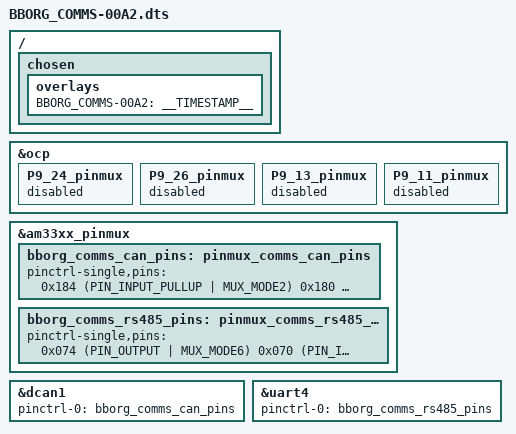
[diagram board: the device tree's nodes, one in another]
/*
 * Copyright (C) 2012,2019 Texas Instruments Incorporated - http://www.ti.com/
 * Copyright (C) 2015 Robert Nelson <robertcnelson@gmail.com>
 * Copyright (C) 2015 Sebastian Jegerås
 *
 * This program is free software; you can redistribute it and/or modify
 * it under the terms of the GNU General Public License version 2 as
 * published by the Free Software Foundation.
 */
/dts-v1/;
/plugin/;

#include <dt-bindings/pinctrl/am33xx.h>
#include <dt-bindings/gpio/gpio.h>

/ {
	/*
	 * Helper to show loaded overlays under: /proc/device-tree/chosen/overlays/
	 */
	fragment@0 {
		target-path="/";
		__overlay__ {

			chosen {
				overlays {
					BBORG_COMMS-00A2 = __TIMESTAMP__;
				};
			};
		};
	};

	/*
	 * Free up the pins used by the cape from the pinmux helpers.
	 */
	fragment@1 {
		target = <&ocp>;
		__overlay__ {
			P9_24_pinmux { status = "disabled"; };	/* P9_24: uart1_txd.d_can1_rx */
			P9_26_pinmux { status = "disabled"; };	/* P9_26: uart1_rxd.d_can1_tx */
			P9_13_pinmux { status = "disabled"; };	/* P9_13: gpmc_wpn.uart4_txd_mux2 */
			P9_11_pinmux { status = "disabled"; };	/* P9_11: gpmc_wait0.uart4_rxd_mux2 */
		};
	};

	fragment@2 {
		target = <&am33xx_pinmux>;
		__overlay__ {
			bborg_comms_can_pins: pinmux_comms_can_pins {
				pinctrl-single,pins = <
					0x184 (PIN_INPUT_PULLUP | MUX_MODE2)	/* P9_24: uart1_txd.d_can1_rx */
					0x180 (PIN_OUTPUT_PULLUP | MUX_MODE2)	/* P9_26: uart1_rxd.d_can1_tx */
				>;
			};
			bborg_comms_rs485_pins: pinmux_comms_rs485_pins {
				pinctrl-single,pins = <
					0x074 (PIN_OUTPUT | MUX_MODE6)	/* P9_13: gpmc_wpn.uart4_txd_mux2 */
					0x070 (PIN_INPUT  | MUX_MODE6)	/* P9_11: gpmc_wait0.uart4_rxd_mux2 */
				>;
			};
		};
	};

	fragment@3 {
		target = <&dcan1>;
		__overlay__ {
			status = "okay";
			pinctrl-names = "default";
			pinctrl-0 = <&bborg_comms_can_pins>;
		};
	};
	
	fragment@4 {
		target = <&uart4>;
		__overlay__ {
			status = "okay";
			pinctrl-names = "default";
			pinctrl-0 = <&bborg_comms_rs485_pins>;
			//rs485-rts-delay = <0 0>;
			//rts-gpio = <&gpio3 19 1>; /*  GPIO_ACTIVE_HIGH>; */
			//rs485-rts-active-high;
			//linux,rs485-enabled-at-boot-time;
		};
	};
};
